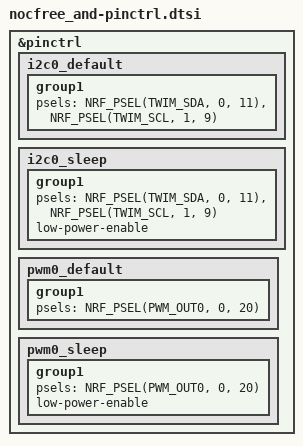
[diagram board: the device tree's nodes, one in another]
/*
 * Copyright (c) 2026 The NocFree ZMK Contributors
 *
 * SPDX-License-Identifier: MIT
 */

/*
 * The key-input I2C bus. NocFree publishes SDA on P0.11 and SCL on P1.09 for
 * both halves; see section 4 of the repository porting guide.
 */
&pinctrl {
    i2c0_default: i2c0_default {
        group1 {
            psels = <NRF_PSEL(TWIM_SDA, 0, 11)>,
                    <NRF_PSEL(TWIM_SCL, 1, 9)>;
        };
    };

    i2c0_sleep: i2c0_sleep {
        group1 {
            psels = <NRF_PSEL(TWIM_SDA, 0, 11)>,
                    <NRF_PSEL(TWIM_SCL, 1, 9)>;
            low-power-enable;
        };
    };

    /*
     * Backlight. Section 4 of the porting guide publishes this as D5 = P0.20
     * on both halves, and the factory v2.3.0 images confirm it: their PWM
     * setup writes PSEL.OUT[0] from g_ADigitalPinMap[5], and index 5 of that
     * table is 20 in both. See docs/backlight.md.
     */
    pwm0_default: pwm0_default {
        group1 {
            psels = <NRF_PSEL(PWM_OUT0, 0, 20)>;
        };
    };

    pwm0_sleep: pwm0_sleep {
        group1 {
            psels = <NRF_PSEL(PWM_OUT0, 0, 20)>;
            low-power-enable;
        };
    };
};
